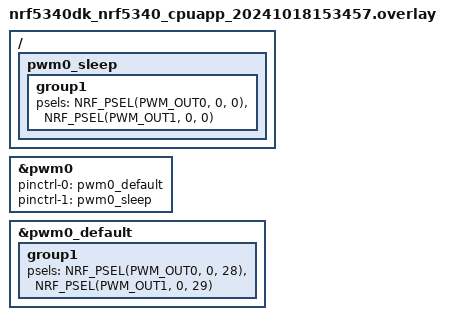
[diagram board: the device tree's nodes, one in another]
&pwm0 {
    status = "okay";
    pinctrl-0 = <&pwm0_default>;
    pinctrl-1 = <&pwm0_sleep>;  // Add a second pin control configuration, usually for sleep or idle mode
    pinctrl-names = "default", "sleep";  // Provide both entries
};

&pwm0_default {
    group1 {
        psels = <NRF_PSEL(PWM_OUT0, 0, 28)>, <NRF_PSEL(PWM_OUT1, 0, 29)>; // Configure PWM output on P0.28 and P0.29
    };
};

/ {
    pwm0_sleep: pwm0_sleep {
        // This group can be empty or set to disconnect pins during sleep
        group1 {
            psels = <NRF_PSEL(PWM_OUT0, 0, 0)>, <NRF_PSEL(PWM_OUT1, 0, 0)>; // Typically set to unused pins or disconnected state
        };
    };
};
